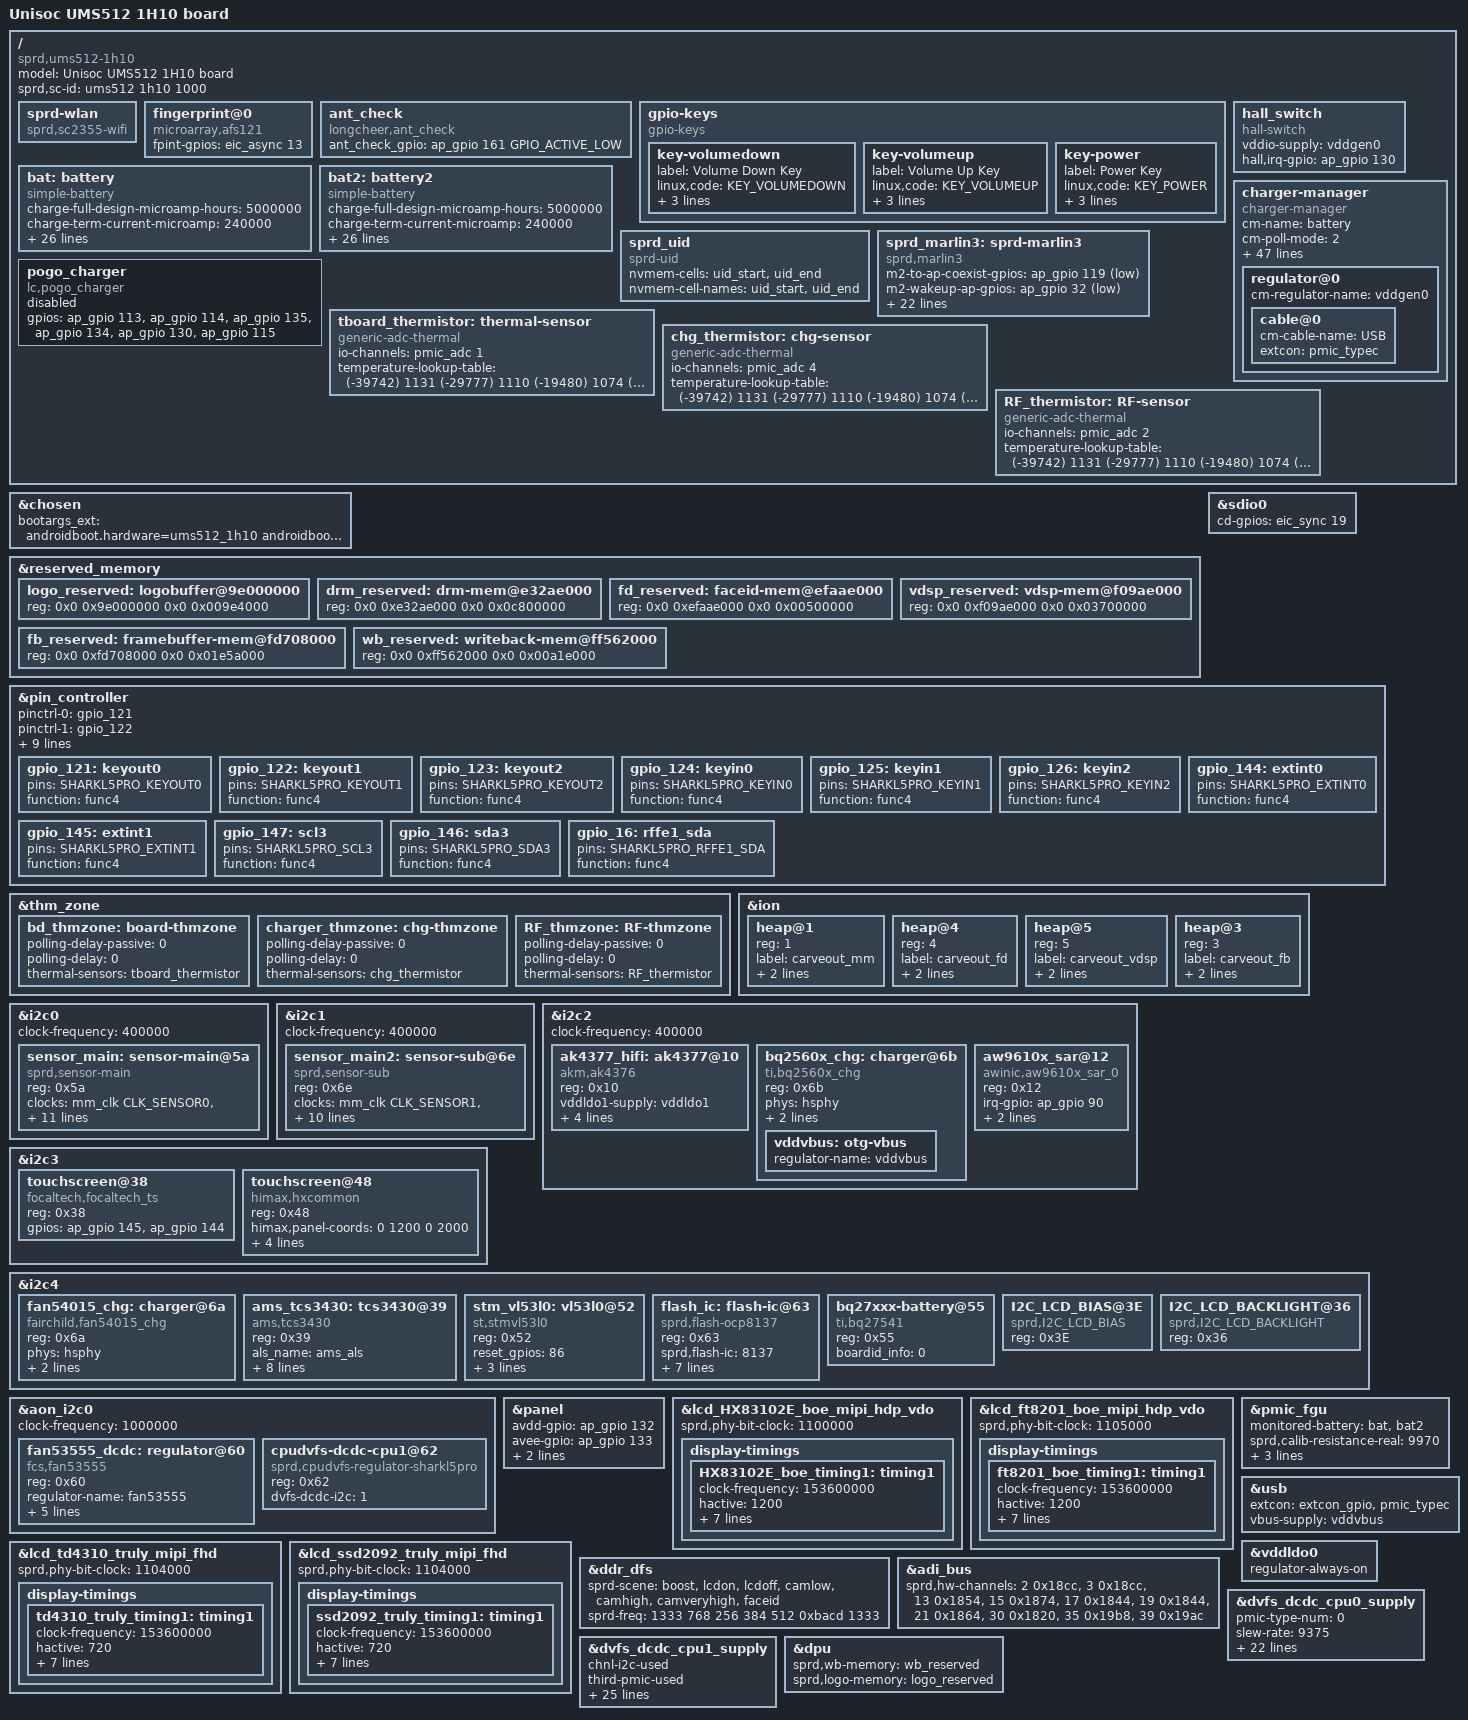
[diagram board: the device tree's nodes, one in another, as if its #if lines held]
/dts-v1/;
/plugin/;

#include <dt-bindings/input/input.h>
#include <dt-bindings/gpio/gpio.h>
#include <dt-bindings/interrupt-controller/arm-gic.h>
#include <dt-bindings/clock/sprd,sharkl5pro-clk.h>
#include <dt-bindings/mfd/sprd,sc2730-regs.h>
#include <dt-bindings/mfd/sprd,sc2730-mask.h>
#include <dt-bindings/wdv/wdv.h>
#include "lcd/lcd_HX83102E_boe_mipi_hdp_vdo.dtsi"
#include "lcd/lcd_ft8201_boe_mipi_hdp_vdo.dtsi"
#include "lcd/lcd_td4310_truly_mipi_fhd.dtsi"
#include "lcd/lcd_ssd2092_truly_mipi_fhd.dtsi"
#include "lcd/lcd_dummy_mipi.dtsi"

/ {

	model = "Unisoc UMS512 1H10 board";
	compatible = "sprd,ums512-1h10";
	sprd,sc-id = "ums512 1h10 1000";

	fragment {
		target-path = "/";
		__overlay__ {
			sprd-wlan {
				compatible = "sprd,sc2355-wifi";
			};

			fingerprint@0 {
				compatible = "microarray,afs121";
				fpint-gpios = <&eic_async 13 0>;
			};

			ant_check {
					compatible = "longcheer,ant_check";
					ant_check_gpio = <&ap_gpio 161 GPIO_ACTIVE_LOW>;
				};
				
			gpio-keys {
				compatible = "gpio-keys";

				key-volumedown {
					label = "Volume Down Key";
					linux,code = <KEY_VOLUMEDOWN>;
					gpios = <&pmic_eic 4 GPIO_ACTIVE_HIGH>;
					debounce-interval = <2>;
					wakeup-source;
				};

				key-volumeup {
					label = "Volume Up Key";
					linux,code = <KEY_VOLUMEUP>;
					gpios = <&ap_gpio 124 GPIO_ACTIVE_LOW>;
					debounce-interval = <2>;
					wakeup-source;
				};

				key-power {
					label = "Power Key";
					linux,code = <KEY_POWER>;
					gpios = <&pmic_eic 1 GPIO_ACTIVE_LOW>;
					debounce-interval = <2>;
					wakeup-source;
				};
			};
			hall_switch {
			   compatible = "hall-switch";
			   vddio-supply= <&vddgen0>;
			   hall,irq-gpio = <&ap_gpio 130 0x0>;
			};
			/*
			pwm_backlight: backlight {
				compatible = "sprd,sharkl5pro-backlight";
				pwms = <&pwms 2 40000>;
				pwm-names = "backlight";
				sprd,max-brightness-level = <880>;
				default-brightness-level = <250>;
				sprd,brightness-scale = <1023>;
				brightness-levels = <
							  0   3   4   5   6   7
					  8   9  10  11  12  13  14  15  16  17
					 18  19  20  21  22  23  24  25  26  27
					 28  29  31  33  35  37  39  41  43  45
					 46  48  50  52  54  56  58  60  62  64
					 66  68  70  72  74  76  78  80  82  84
					 86  88  90  92  94  96  98 100 102 104
					106 108 110 112 114 116 118 120 122 124
					126 128 130 132 134 136 138 140 142 144
					146 148 150 152 154 156 158 160 162 164
					166 169 172 175 178 181 184 187 190 193
					196 199 202 205 208 211 214 217 220 223
					226 229 232 235 238 241 244 247 250 253
					256 259 262 265 268 271 274 277 280 283
					286 290 294 298 302 306 310 314 318 322
					326 330 334 338 342 346 350 354 358 362
					366 370 374 378 382 386 390 394 398 402
					406 410 414 418 422 426 430 434 438 442
					446 451 456 461 466 471 476 481 486 491
					496 501 506 511 516 521 526 531 536 541
					546 551 556 561 566 571 576 581 586 591
					596 601 606 611 616 621 626 631 636 641
					646 652 658 664 670 676 682 688 694 700
					706 712 718 724 730 736 742 748 754 760
					766 772 778 784 790 796 802 808 814 820
					826 832 838 844 850 856 862 868 874 880
				>;
			};
			*/
			bat: battery {	//飞毛腿
				compatible = "simple-battery";
				charge-full-design-microamp-hours = <5000000>;
				charge-term-current-microamp = <240000>;
				constant_charge_voltage_max_microvolt = <4432000>;
				factory-internal-resistance-micro-ohms = <151000>;
				voltage-min-design-microvolt = <3457000>;
				ocv-capacity-celsius = <25>;
				ocv-capacity-table-0 = <4386000 100>, <4328000 95>, <4270000 90>,
							<4211000 85>, <4153000 80>, <4098000 75>,
							<4048000 70>, <4000000 65>, <3957000 60>,
							<3897000 55>, <3862000 50>, <3837000 45>,
							<3816000 40>, <3800000 35>, <3785000 30>,
							<3768000 25>, <3749000 20>, <3723000 15>,
							<3694000 10>, <3683000 5>, <3400000 0>;
				voltage-temp-table = <1076000 800>, <970000 850>, <855000 900>,
							  <764000 950>, <672000 1000>, <584000 1050>,
							  <504000 1100>, <445000 1150>, <382000 1200>,
							  <322000 1250>, <273000 1300>, <243000 1350>,
							  <208000 1400>, <179000 1450>, <156000 1500>,
							  <134000 1550>, <116000 1600>, <100000 1650>;
				capacity-temp-table = <45 100>, <25 100>, <10 100>, <0 92>, <(-10) 87>, <(-20) 65>;
				resistance-temp-table = <45 100>, <25 100>, <10 248>, <0 662>, <(-10) 662>, <(-20) 662>;
				charge-sdp-current-microamp = <500000 500000>;
				charge-dcp-current-microamp = <2100000 2100000>;
				charge-cdp-current-microamp = <1500000 1500000>;
				charge-unknown-current-microamp = <500000 500000>;
			};

			bat2: battery2 {	//宁德
				compatible = "simple-battery";
				charge-full-design-microamp-hours = <5000000>;
				charge-term-current-microamp = <240000>;
				constant_charge_voltage_max_microvolt = <4432000>;
				factory-internal-resistance-micro-ohms = <123000>;
				voltage-min-design-microvolt = <3448000>;
				ocv-capacity-celsius = <25>;
				ocv-capacity-table-0 = <4390000 100>, <4327000 95>, <4269000 90>,
							<4209000 85>, <4152000 80>, <4098000 75>,
							<4048000 70>, <4002000 65>, <3960000 60>,
							<3905000 55>, <3866000 50>, <3840000 45>,
							<3820000 40>, <3804000 35>, <3790000 30>,
							<3772000 25>, <3752000 20>, <3726000 15>,
							<3697000 10>, <3684000 5>, <3400000 0>;
				voltage-temp-table = <1076000 800>, <970000 850>, <855000 900>,
							  <764000 950>, <672000 1000>, <584000 1050>,
							  <504000 1100>, <445000 1150>, <382000 1200>,
							  <322000 1250>, <273000 1300>, <243000 1350>,
							  <208000 1400>, <179000 1450>, <156000 1500>,
							  <134000 1550>, <116000 1600>, <100000 1650>;
				capacity-temp-table = <45 100>, <25 100>, <10 99>, <0 91>, <(-10) 87>, <(-20) 72>;
				resistance-temp-table = <45 100>, <25 100>, <10 197>, <0 813>, <(-10) 813>, <(-20) 813>;
				charge-sdp-current-microamp = <500000 500000>;
				charge-dcp-current-microamp = <2100000 2100000>;
				charge-cdp-current-microamp = <1500000 1500000>;
				charge-unknown-current-microamp = <500000 500000>;
			};

			charger-manager {
				compatible = "charger-manager";
				cm-name = "battery";
				cm-poll-mode = <2>;
				cm-poll-interval = <15000>;
				cm-battery-stat = <2>;

				cm-fullbatt-vchkdrop-ms = <30000>;
				cm-fullbatt-vchkdrop-volt = <60000>;
				cm-fullbatt-voltage = <4400000>;
				cm-fullbatt-current = <240000>;
				cm-first-fullbatt-current = <300000>;
				cm-fullbatt-capacity = <100>;

				cm-num-chargers = <1>;
				cm-chargers = "bq2560x_charger";
				cm-fuel-gauge = "sc27xx-fgu";

				/* in deci centigrade */
				cm-battery-cold = <200>;
				cm-battery-cold-in-minus;
				cm-battery-hot = <800>;
				cm-battery-temp-diff = <100>;

				/* Allow charging for 18hours */
				cm-charging-max = <64800000>;
				/* recovery charging after stop charging 45min */
				cm-discharging-max = <2700000>;

				/* the interval to feed charger watchdog */
				cm-wdt-interval = <60>;

				/* drop voltage in microVolts to allow shutdown */
				cm-shutdown-voltage = <3100000>;

				/* when 99% of the time is exceeded, it will be forced to 100% */
				cm-tickle-time-out = <1500>;

				/* how much time to allow capacity change */
				cm-one-cap-time = <30>;
				cm-thermal-zone = "board-thmzone";
				/* when the safe charging voltage is exceeded, stop charging */
				cm-charge-voltage-max = <6500000>;
				/* drop voltage in microVolts to restart charging */
				cm-charge-voltage-drop = <700000>;
				cm-dcp-jeita-temp-table = <1000 1020 0 4432000>, <1150 1160 1000000 4432000>,
					<1450 1440 2100000 4432000>, <1500 1480 2100000 4200000>;
				cm-sdp-jeita-temp-table = <1000 1020 0 4432000>, <1150 1160 500000 4432000>,
					<1450 1440 500000 4432000>, <1500 1480 500000 4200000>;
				cm-cdp-jeita-temp-table = <1000 1020 0 4432000>, <1150 1160 1000000 4432000>,
					<1450 1440 1500000 4432000>, <1500 1480 1500000 4200000>;
				cm-unknown-jeita-temp-table = <1000 1020 0 4432000>, <1150 1160 500000 4432000>,
					<1450 1440 500000 4432000>, <1500 1480 500000 4200000>;

				monitored-battery = <&bat &bat2>;
				cm-capacity-track;

				cm-cap-remap-table = <1 2 3>, <2 3 2>, <98 99 2>, <99 100 3>;

				bat-maintian-table = <56 4208000 80>, <54 4304000 90>, <30 4368000 95>, <0 4432000 100>;

				regulator@0 {
					cm-regulator-name = "vddgen0";
					cable@0 {
						cm-cable-name = "USB";
						extcon = <&pmic_typec>;
					};
				};
			};

			sprd_uid {
				compatible = "sprd-uid";
				nvmem-cells = <&uid_start>, <&uid_end>;
				nvmem-cell-names = "uid_start", "uid_end";
			};

			sprd_marlin3: sprd-marlin3 {
				compatible = "sprd,marlin3";
				m2-to-ap-coexist-gpios = <&ap_gpio 119 GPIO_ACTIVE_LOW>;
				m2-wakeup-ap-gpios = <&ap_gpio 32 GPIO_ACTIVE_LOW>;
				permit-ap-send-gpios = <&ap_gpio 121 GPIO_ACTIVE_LOW>;
				reset-gpios = <&ap_gpio 95 GPIO_ACTIVE_LOW>;
				enable-gpios = <&ap_gpio 143 GPIO_ACTIVE_LOW>;
				m2-to-ap-irq-gpios = <&ap_gpio 94 GPIO_ACTIVE_LOW>;
				avdd12-supply = <&vddwcn>;
				avdd33-supply = <&vddwifipa>;
				dcxo18-supply = <&vddsim2>;

				clock-names = "clk_32k","source","enable";
				clocks = <&aon_clk CLK_AUX0>,
					 <&ext_32k>,
					 <&aonapb_gate CLK_AUX0_EB>;

				sdhci-name = <&sdio1>;
				sprd,btwf-file-name = "/dev/block/platform/soc/soc:ap-apb/71400000.sdio/by-name/wcnmodem";
				sprd,gnss-file-name = "/dev/block/platform/soc/soc:ap-apb/71400000.sdio/by-name/gnssmodem";
				adma-tx;
				adma-rx;
				/*
				 * bound parameter:
				 * [0]:addr offset, [1]:mask, [2]:unboundval, [3]:boundval
				 */
				avdd12-parent-bound-chip = <REG_ANA_SLP_DCDC_PD_CTRL MASK_ANA_SLP_DCDCGEN1_PD_EN 0x0 MASK_ANA_SLP_DCDCGEN1_PD_EN>;
				avdd12-bound-wbreq = <REG_ANA_LDO_XTL_EN10 MASK_ANA_LDO_VDDWCN_EXT_XTL3_EN 0x0 MASK_ANA_LDO_VDDWCN_EXT_XTL3_EN>;
				avdd33-bound-wbreq = <REG_ANA_LDO_XTL_EN11 MASK_ANA_LDO_VDDWIFIPA_EXT_XTL3_EN 0x0 MASK_ANA_LDO_VDDWIFIPA_EXT_XTL3_EN>;
			};

			pogo_charger: pogo_charger {
				compatible = "lc,pogo_charger";
				status = "disable";
				gpios = <&ap_gpio 113 GPIO_ACTIVE_HIGH //GPIO_POGO_EN 113
				 		&ap_gpio 114 GPIO_ACTIVE_HIGH //POGO_INT 114
				 		&ap_gpio 135 GPIO_ACTIVE_HIGH //GPIO_USB_EN 135
				 		&ap_gpio 134 GPIO_ACTIVE_HIGH //USB_INT 134
				 		&ap_gpio 130 GPIO_ACTIVE_HIGH //DCDC_OVP_EN 130
				 		&ap_gpio 115 GPIO_ACTIVE_HIGH //POGO_OCP_INT 115
				 >;
			};

			tboard_thermistor:thermal-sensor {
				compatible = "generic-adc-thermal";
				#thermal-sensor-cells = <0>;
				io-channels = <&pmic_adc 1>;
				io-channel-names = "sensor-channel";
				temperature-lookup-table = <    (-39742) 1131
								(-29777) 1110
								(-19480) 1074
								(-4679) 983
								10110 838
								24805 654
								44922 413
								54903 316
								64895 238
								74884 178
								84883 133
								94883 100
								104880 75
								114889 57
								124872 43 >;
			};

			chg_thermistor:chg-sensor {
				compatible = "generic-adc-thermal";
				#thermal-sensor-cells = <0>;
				io-channels = <&pmic_adc 4>; //根据实际硬件接口配置
				io-channel-names = "sensor-channel";
				temperature-lookup-table = < (-39742) 1131 //根据实际使用的 NTC 配置
					(-29777) 1110
					(-19480) 1074
					(-4679) 983
					10110 838
					24805 654
					44922 413
					54903 316
					64895 238
					74884 178
					84883 133
					94883 100
					104880 75
					114889 57
					124872 43 >;
			};

			RF_thermistor:RF-sensor {
				compatible = "generic-adc-thermal";
				#thermal-sensor-cells = <0>;
				io-channels = <&pmic_adc 2>; //根据实际硬件接口配置
				io-channel-names = "sensor-channel";
				temperature-lookup-table = < (-39742) 1131 //根据实际使用的 NTC 配置
					(-29777) 1110
					(-19480) 1074
					(-4679) 983
					10110 838
					24805 654
					44922 413
					54903 316
					64895 238
					74884 178
					84883 133
					94883 100
					104880 75
					114889 57
					124872 43 >;
			};
		};
	};	
};

&chosen {
	bootargs_ext = "androidboot.hardware=ums512_1h10 androidboot.dtbo_idx=0";
};

&reserved_memory {

	logo_reserved: logobuffer@9e000000{
		reg = <0x0 0x9e000000 0x0 0x009e4000>;
	};

#ifdef BSP_KERNEL_CONFIG_WIDEVINE_L1
	drm_reserved: drm-mem@e32ae000 {
		reg = <0x0 0xe32ae000 0x0 0x0c800000>;
	};
#endif

	fd_reserved: faceid-mem@efaae000 {
		reg = <0x0 0xefaae000 0x0 0x00500000>;
	};

	vdsp_reserved: vdsp-mem@f09ae000 {
		reg = <0x0 0xf09ae000 0x0 0x03700000>;
	};
/*
	gpu_reserved: gpu-mem@fb8ae000 {
		reg = <0x0 0xfb8ae000 0x0 0x01e5a000>;
	};
*/

	fb_reserved: framebuffer-mem@fd708000 {
		reg = <0x0 0xfd708000 0x0 0x01e5a000>;
	};

	wb_reserved: writeback-mem@ff562000 {
		reg = <0x0 0xff562000 0x0 0x00a1e000>;
	};

};

&sdio0 {
	cd-gpios = <&eic_sync 19 GPIO_ACTIVE_HIGH>;
};

&pin_controller {
	pinctrl-names =
	/* keyout0 ~ keyout2 */
	"gpio_121", "gpio_122", "gpio_123",
	/* keyin0 ~ keyin2 */
	"gpio_124", "gpio_125", "gpio_126",
	/* extint0, extint1, scl3, sda3, sda */
	"gpio_144", "gpio_145", "gpio_146", "gpio_147", "gpio_16";

	pinctrl-0 = <&gpio_121>;
	pinctrl-1 = <&gpio_122>;
	pinctrl-2 = <&gpio_123>;
	pinctrl-3 = <&gpio_124>;
	pinctrl-4 = <&gpio_125>;
	pinctrl-5 = <&gpio_126>;
	pinctrl-6 = <&gpio_144>;
	pinctrl-7 = <&gpio_145>;
	pinctrl-8 = <&gpio_146>;
	pinctrl-9 = <&gpio_147>;
	pinctrl-10 = <&gpio_16>;

	gpio_121: keyout0 {
		pins = "SHARKL5PRO_KEYOUT0";
		function = "func4";
	};

	gpio_122: keyout1 {
		pins = "SHARKL5PRO_KEYOUT1";
		function = "func4";
	};

	gpio_123: keyout2 {
		pins = "SHARKL5PRO_KEYOUT2";
		function = "func4";
	};

	gpio_124: keyin0 {
		pins = "SHARKL5PRO_KEYIN0";
		function = "func4";
	};

	gpio_125: keyin1 {
		pins = "SHARKL5PRO_KEYIN1";
		function = "func4";
	};

	gpio_126: keyin2 {
		pins = "SHARKL5PRO_KEYIN2";
		function = "func4";
	};

	gpio_144: extint0 {
		pins = "SHARKL5PRO_EXTINT0";
		function = "func4";
	};

	gpio_145: extint1 {
		pins = "SHARKL5PRO_EXTINT1";
		function = "func4";
	};

	gpio_147: scl3 {
		pins = "SHARKL5PRO_SCL3";
		function = "func4";
	};

	gpio_146: sda3 {
		pins = "SHARKL5PRO_SDA3";
		function = "func4";
	};

	gpio_16: rffe1_sda {
		pins = "SHARKL5PRO_RFFE1_SDA";
		function = "func4";
	};
};

&thm_zone {
	bd_thmzone: board-thmzone {
		polling-delay-passive = <0>;
		polling-delay = <0>;
		thermal-sensors = <&tboard_thermistor>;
	};

	charger_thmzone: chg-thmzone {
		polling-delay-passive = <0>;
		polling-delay = <0>;
		thermal-sensors = <&chg_thermistor>;
	};

	RF_thmzone: RF-thmzone {
		polling-delay-passive = <0>;
		polling-delay = <0>;
		thermal-sensors = <&RF_thermistor>;
	};
};

&ion {
#ifdef BSP_KERNEL_CONFIG_WIDEVINE_L1
	heap@1 {
		reg = <1>;
		label = "carveout_mm";
		type = <2>;
		memory-region = <&drm_reserved>;
	};
#endif

	heap@4 {
		reg = <4>;
		label = "carveout_fd";
		type = <2>;
		memory-region = <&fd_reserved>;
	};

	heap@5 {
		reg = <5>;
		label = "carveout_vdsp";
		type = <2>;
		memory-region = <&vdsp_reserved>;
	};
};

&i2c0 {
	status = "okay";
	clock-frequency = <400000>;

	sensor_main: sensor-main@5a {
		compatible = "sprd,sensor-main";
		reg = <0x5a>;
		clock-names = "clk_src","sensor_eb",
			"clk_96m","clk_76m8",
			"clk_48m","clk_26m";
		clocks = <&mm_clk CLK_SENSOR0>,<&mm_gate CLK_MM_SENSOR0_EB>,
				<&pll2 CLK_TWPLL_96M>,<&pll2 CLK_TWPLL_76M8>,
				<&pll2 CLK_TWPLL_48M>,<&ext_26m>;
		vddio-supply = <&vddcamio>;
		vddcama-supply = <&vddcama0>;
		vddcamd-supply = <&vddcamd0>;
		vddcammot-supply = <&vddcammot>;
		reset-gpios = <&ap_gpio 44 0>;
		power-down-gpios = <&ap_gpio 46 0>;
		sprd,phyid = <0>;
		csi = <&csi0>;
	};
/*
	sensor_sub: sensor-sub@5a {
		compatible = "sprd,sensor-sub";
		reg = <0x5a>;
		clock-names = "clk_src","sensor_eb",
			"clk_96m","clk_76m8",
			"clk_48m","clk_26m";
		clocks = <&mm_clk CLK_SENSOR0>,<&mm_gate CLK_MM_SENSOR0_EB>,
				<&pll2 CLK_TWPLL_96M>,<&pll2 CLK_TWPLL_76M8>,
				<&pll2 CLK_TWPLL_48M>,<&ext_26m>;
		vddio-supply = <&vddcamio>;
		vddcama-supply = <&vddcama0>;
		vddcamd-supply = <&vddcamd0>;
		vddcammot-supply = <&vddcammot>;
		reset-gpios = <&ap_gpio 41 0>;
		power-down-gpios = <&ap_gpio 40 0>;
		mipi-switch-en-gpios = <&ap_gpio 55 0>;
		//mipi-switch-mode-gpios = <&ap_gpio 8 0>;
		sprd,phyid = <1>;
		csi = <&csi0>;
	}; */
};

&i2c1 {
	status = "okay";
	clock-frequency = <400000>;

	sensor_main2: sensor-sub@6e {
		compatible = "sprd,sensor-sub";
		reg = <0x6e>;
		clock-names = "clk_src","sensor_eb",
			"clk_96m","clk_76m8",
			"clk_48m","clk_26m";
		clocks = <&mm_clk CLK_SENSOR1>,<&mm_gate CLK_MM_SENSOR1_EB>,
				<&pll2 CLK_TWPLL_96M>,<&pll2 CLK_TWPLL_76M8>,
				<&pll2 CLK_TWPLL_48M>,<&ext_26m>;
		vddio-supply = <&vddcamio>;
		vddcama-supply = <&vddcama0>;
		vddcamd-supply = <&vddcamd0>;
		//vddcammot-supply = <&vddcammot>;
		//avdd-gpios = <&ap_gpio 33 0>;
		//mot-gpios = <&ap_gpio 88 0>;
		reset-gpios = <&ap_gpio 45 0>;
		power-down-gpios = <&ap_gpio 40 0>;
		//mipi-switch-en-gpios = <&ap_gpio 55 0>;
		//mipi-switch-mode-gpios = <&ap_gpio 8 0>;
		sprd,phyid = <3>;
		csi = <&csi0>;
	};
/*
	sensor_sub2: sensor-sub2@6e {
		compatible = "sprd,sensor-sub2";
		reg = <0x6e>;
		clock-names = "clk_src","sensor_eb",
			"clk_96m","clk_76m8",
			"clk_48m","clk_26m";
		clocks = <&mm_clk CLK_SENSOR1>,<&mm_gate CLK_MM_SENSOR1_EB>,
			<&pll2 CLK_TWPLL_96M>,<&pll2 CLK_TWPLL_76M8>,
			<&pll2 CLK_TWPLL_48M>,<&ext_26m>;
		vddio-supply = <&vddcamio>;
		vddcama-supply = <&vddcama1>;
		vddcamd-supply = <&vddcamd1>;
		vddcammot-supply = <&vddcammot>;
		mot-gpios = <&ap_gpio 88 0>;
		reset-gpios = <&ap_gpio 41 0>;
		power-down-gpios = <&ap_gpio 40 0>;
		sprd,phyid = <2>;
		csi = <&csi2>;
	};

	sensor_main3: sensor-main3@6c {
		compatible = "sprd,sensor-main3";
		reg = <0x6c>;
		clock-names = "clk_src","sensor_eb",
			"clk_96m","clk_76m8",
			"clk_48m","clk_26m";
		clocks = <&mm_clk CLK_SENSOR1>,<&mm_gate CLK_MM_SENSOR1_EB>,
				<&pll2 CLK_TWPLL_96M>,<&pll2 CLK_TWPLL_76M8>,
				<&pll2 CLK_TWPLL_48M>,<&ext_26m>;
		vddio-supply = <&vddcamio>;
		vddcama-supply = <&vddcama1>;
		vddcamd-supply = <&vddcamd1>;
		vddcammot-supply = <&vddcammot>;
		mot-gpios = <&ap_gpio 88 0>;
		reset-gpios = <&ap_gpio 41 0>;
		power-down-gpios = <&ap_gpio 40 0>;
		sprd,phyid = <2>;
		csi = <&csi2>;
	}; */
};

&i2c2 {
	status = "okay";
	clock-frequency = <400000>;

	ak4377_hifi: ak4377@10 {
		compatible = "akm,ak4376";
		reg = <0x10>;
		#sound-dai-cells = <1>;
		vddldo1-supply = <&vddldo1>;
		sprd,vddldo1-voltage = <1800000>;
		ak4377,pdn-gpio = <&ap_gpio 116 GPIO_ACTIVE_HIGH>;

		clock-names = "clk_48M", "source", "enable";
		clocks = <&aon_clk CLK_AUX1>,
			 <&pll2 CLK_TWPLL_19M2>,
			 <&aonapb_gate CLK_AUX1_EB>;
	};

	bq2560x_chg: charger@6b {
		compatible = "ti,bq2560x_chg";
		reg = <0x6b>;
		phys = <&hsphy>;
		monitored-battery = <&bat &bat2>;
		extcon = <&extcon_gpio>;
		vddvbus:otg-vbus {
			regulator-name = "vddvbus";
		};
	};

	aw9610x_sar@12 {
		compatible = "awinic,aw9610x_sar_0";
		reg = <0x12>;
		irq-gpio = <&ap_gpio 90 0>;
		aw9610x,using-firmware;
		sar-num = < 0 >;
		//vcc-supply = <&pm8953_l6>;
		status = "okay";
	};

};

&i2c3 {
	status = "okay";
#if 0
	touchscreen@20 {
		compatible = "synaptics,dsx";
		reg = <0x20>;
		gpios = <&ap_gpio 145 GPIO_ACTIVE_HIGH
			&ap_gpio 144 GPIO_ACTIVE_HIGH>;
	};

	touchscreen@53 {
		compatible = "solomon,ssd20xx";
		reg = <0x53>;
		gpios = <&ap_gpio 145 GPIO_ACTIVE_HIGH
			&ap_gpio 144 GPIO_ACTIVE_HIGH>;
	};
#endif
	touchscreen@38 {
		compatible = "focaltech,focaltech_ts";
		reg = <0x38>;
		gpios = <&ap_gpio 145 GPIO_ACTIVE_HIGH //CTP_RST 145
				 &ap_gpio 144 GPIO_ACTIVE_HIGH>; //CTP_INT 144
	};

     touchscreen@48 {
              compatible = "himax,hxcommon";
	
              reg = <0x48>;
              
              himax,panel-coords = <0 1200 0 2000>;
              himax,display-cords = <0 1200 0 2000>;
              himax,irq-gpio = <&eic_async 0 GPIO_ACTIVE_HIGH>;
              himax,rst-gpio = <&ap_gpio 145 GPIO_ACTIVE_HIGH>;
              report_type = <1>;
      };
};

&i2c4 {
	status = "okay";

	fan54015_chg: charger@6a {
		compatible = "fairchild,fan54015_chg";
		reg = <0x6a>;
		phys = <&hsphy>;
		monitored-battery = <&bat>;
		extcon = <&extcon_gpio>;
		//vddvbus:otg-vbus {
		//	regulator-name = "vddvbus";
		//};
	};

	ams_tcs3430: tcs3430@39 {
		compatible = "ams,tcs3430";
		reg = <0x39>;
		als_name = "ams_als";
		persist = <0>;
		als_time_ms = <100>;
		als_gain = <64>;
		int_config = <0>;
		als_can_wake = <1>;
		irq_gpios = <112>;
		interrupt-parent = <&ap_gpio>;
		interrupts = <112 IRQ_TYPE_LEVEL_LOW>;
	};

	stm_vl53l0: vl53l0@52 {
		compatible = "st,stmvl53l0";
		reg = <0x52>;
		reset_gpios = <86>;
		irq_gpios = <87>;
		interrupt-parent = <&ap_gpio>;
		interrupts = <87 IRQ_TYPE_LEVEL_LOW>;
	};

	flash_ic: flash-ic@63 {
		compatible = "sprd,flash-ocp8137";
		reg = <0x63>;
		sprd,flash-ic = <8137>;
		sprd,torch = <1>;
		sprd,preflash = <1>;
		sprd,highlight = <1>;
		sprd,torch-level = <128>;
		sprd,preflash-level = <128>;
		sprd,highlight-level = <128>;
		sprd,lvfm-enable = <1>;
		//flash-chip-en-gpios = <&ap_gpio 136 0>;
		//flash-torch-en-gpios = <&ap_gpio 139 0>;
		//flash-en-gpios = <&ap_gpio 137 0>;
		//flash-sync-gpios = <&ap_gpio 138 0>;
	};

	bq27xxx-battery@55 {
		compatible = "ti,bq27541";
		reg = <0x55>;
		boardid_info = <0>;
		//status = "disabled";
	};

	I2C_LCD_BIAS@3E {
		compatible = "sprd,I2C_LCD_BIAS" ;
		reg = <0x3E> ;
		status = "okay" ;
	};
	I2C_LCD_BACKLIGHT@36 {
		compatible = "sprd,I2C_LCD_BACKLIGHT" ;
		reg = <0x36> ;
		status = "okay" ;
	};

};

&aon_i2c0 {
	status = "okay";
	clock-frequency = <1000000>;

	fan53555_dcdc: regulator@60 {
		compatible = "fcs,fan53555";
		reg = <0x60>;
		regulator-name = "fan53555";
		regulator-min-microvolt = <600000>;
		regulator-max-microvolt = <1230000>;
		regulator-ramp-delay = <64000>;
		regulator-always-on;
		fcs,suspend-voltage-selector = <1>;
	};

	/* A virtual i2c device */
	cpudvfs-dcdc-cpu1@62{
		compatible = "sprd,cpudvfs-regulator-sharkl5pro";
		reg = <0x62>;
		dvfs-dcdc-i2c = <1>;
	};
};

&panel {
	//sprd,backlight = <&pwm_backlight>;
	avdd-gpio = <&ap_gpio 132 GPIO_ACTIVE_HIGH>;
	avee-gpio = <&ap_gpio 133 GPIO_ACTIVE_HIGH>;
	reset-gpio = <&ap_gpio 50 GPIO_ACTIVE_HIGH>;
	BL-gpio = <&ap_gpio 93 GPIO_ACTIVE_HIGH>;
};
/*
&dpu {
	sprd,backlight = <&pwm_backlight>;
};
*/
&lcd_HX83102E_boe_mipi_hdp_vdo {
	sprd,phy-bit-clock = <1100000>;  /* kbps */

	display-timings {
		HX83102E_boe_timing1: timing1 {
			clock-frequency = <153600000>;
			hactive = <1200>;
			vactive = <1920>;
			hback-porch = <20>;
			hfront-porch = <20>;
			vback-porch = <28>;
			vfront-porch = <220>;
			hsync-len = <10>;
			vsync-len = <8>;
		};
	};
};
&lcd_ft8201_boe_mipi_hdp_vdo {
	sprd,phy-bit-clock = <1105000>;  /* kbps */

	display-timings {
		ft8201_boe_timing1: timing1 {
			clock-frequency = <153600000>;
			hactive = <1200>;
			vactive = <1920>;
			hback-porch = <12>;
			hfront-porch = <27>;
			vback-porch = <32>;
			vfront-porch = <155>;
			hsync-len = <8>;
			vsync-len = <8>;
		};
	};
};

&lcd_td4310_truly_mipi_fhd {
	sprd,phy-bit-clock = <1104000>;  /* kbps */

	display-timings {
		td4310_truly_timing1: timing1 {
			clock-frequency = <153600000>;
			hactive = <720>;
			vactive = <1440>;
			hback-porch = <20>;
			hfront-porch = <50>;
			vback-porch = <28>;
			vfront-porch = <4>;
			hsync-len = <2>;
			vsync-len = <2>;
		};
	};
};

&lcd_ssd2092_truly_mipi_fhd {
	sprd,phy-bit-clock = <1104000>;  /* kbps */

	display-timings {
		ssd2092_truly_timing1: timing1 {
			clock-frequency = <153600000>;
			hactive = <720>;
			vactive = <1440>;
			hback-porch = <20>;
			hfront-porch = <20>;
			vback-porch = <43>;
			vfront-porch = <76>;
			hsync-len = <4>;
			vsync-len = <1>;
		};
	};
};

&ddr_dfs {
	sprd-scene = "boost", "lcdon", "lcdoff", "camlow",
		"camhigh", "camveryhigh", "faceid";
	sprd-freq = <1333 768 256 384 512 0xbacd 1333>;
};

&pmic_fgu {
	monitored-battery = <&bat &bat2>;
	sprd,calib-resistance-real = <9970>;
	sprd,calib-resistance-spec = <20000>;
	first-calib-voltage = <3558000>;
	first-calib-capacity = <50>;
};

&usb {
	extcon = <&extcon_gpio>, <&pmic_typec>;
	vbus-supply = <&vddvbus>;
};

&vddldo0 {
	regulator-always-on;
};

&adi_bus {
	sprd,hw-channels = <2 0x18cc>, <3 0x18cc>, <13 0x1854>, <15 0x1874>,
			 <17 0x1844>,<19 0x1844>, <21 0x1864>, <30 0x1820>,
			 <35 0x19b8>, <39 0x19ac>;
};

&dvfs_dcdc_cpu0_supply {
	pmic-type-num = <0>;
	slew-rate = <9375>; /* 9375uV/us */
	top-dvfs-adi-state = <0x70 0 0xf>;
	voltage-grade-num = <7>;
	voltage-grade = <0 0xf0 0xf4 0 0x1ff>,
		<1 0xf0 0xf4 9 0x1ff>,
		<2 0x100 0xf4 18 0x1ff>,
		<3 0x110 0xf8 0 0x1ff>,
		<4 0x120 0xf8 9 0x1ff>,
		<5 0x130 0xf8 18 0x1ff>,
		<6 0x140 0xfc 0 0x1ff>;
	voltage-up-delay = <50 0x58 0 0xffff 0x600>,
		<100 0x58 16 0xffff 0xa00>,
		<150 0x54 0 0xffff 0xf00>,
		<200 0x54 16 0xffff 0x1400>,
		<250 0x50 0 0xffff 0x1900>,
		<300 0x50 16 0xffff 0x1e00>,
		<350 0x110 0 0xffff 0x2300>;
	voltage-down-delay = <50 0x64 0 0xffff 0x600>,
		<100 0x64 16 0xffff 0xa00>,
		<150 0x60 0 0xffff 0xf00>,
		<200 0x60 16 0xffff 0x1400>,
		<250 0x5c 0 0xffff 0x1900>,
		<300 0x5c 16 0xffff 0x1e00>,
		<350 0x114 0 0xffff 0x2300>;
	tuning-latency-us = <0>;
	chnl-in-i2c = <0>;
};

&dvfs_dcdc_cpu1_supply {
	chnl-i2c-used;
	third-pmic-used;
	pmic-type-num = <2>;
	slew-rate = <4000>; /* 4000uV/us */
	supply-type-sel = <0x120 0 1>;
	top-dvfs-i2c-state = <0x9c 4 0xf>;
	voltage-grade-num = <6>;
	voltage-grade = <0 0x0f 0x12c 0 0x7f>,
		<1 0x14 0x12c 7 0x7f>,
		<2 0x19 0x12c 14 0x7f>,
		<3 0x1e 0x12c 21 0x7f>,
		<4 0x23 0x130 0 0x7f>,
		<5 0x28 0x130 7 0x7f>;
	voltage-up-delay = <50 0x84 0 0xffff 0x1600>,
		<100 0x84 16 0xffff 0x1a00>,
		<150 0x80 0 0xffff 0x1f00>,
		<200 0x80 16 0xffff 0x2400>,
		<250 0x7c 0 0xffff 0x2900>,
		<300 0x7c 16 0xffff 0x2e00>,
		<350 0x118 0 0xffff 0x3300>;
	voltage-down-delay = <50 0x90 0 0xffff 0x600>,
		<100 0x90 16 0xffff 0xa00>,
		<150 0x8c 0 0xffff 0xf00>,
		<200 0x8c 16 0xffff 0x1400>,
		<250 0x88 0 0xffff 0x1900>,
		<300 0x88 16 0xffff 0x1e00>,
		<350 0x11c 0 0xffff 0x2300>;
	tuning-latency-us = <0>;
	chnl-in-i2c = <1>;
};

&ion {
	heap@3 {
		reg = <3>;
		label = "carveout_fb";
		type = <2>;
		memory-region = <&fb_reserved>;
	};
};

&dpu {
	sprd,wb-memory = <&wb_reserved>;
	sprd,logo-memory = <&logo_reserved>;
};
